# nrf51 register map
Vendor: Nordic Semiconductor; Series: nrf51; File version: 522
CPU: CM0 r3p1, little endian, no MPU, no FPU, 2 interrupt priority bits
Registers are 32-bit, read-write, reset 0x0 unless marked. A register's access mark holds for its fields unless they carry their own. Offsets are from the block's base; [hi:lo] are bit positions; 'fields as' and 'values as' point back to an identical list.

## SPI0 — SPI master 0.
Base 0x40003000
Same registers: SPI1 0x40004000
0x108 EVENTS_READY — TXD byte sent and RXD byte received.
0x304 INTENSET — Interrupt enable set register.
  [2] READY — Enable interrupt on READY event.
    on read: 0=Disabled (Interrupt disabled.); 1=Enabled (Interrupt enabled.) | on write: 1=Set (Enable interrupt on write.)
0x308 INTENCLR — Interrupt enable clear register.
  [2] READY — Disable interrupt on READY event.
    on read: 0=Disabled (Interrupt disabled.); 1=Enabled (Interrupt enabled.) | on write: 1=Clear (Disable interrupt on write.)
0x500 ENABLE — Enable SPI.
  [2:0] ENABLE — Enable or disable SPI.
    0=Disabled SPI; 1=Enabled (Enable SPI.)
0x508 PSELSCK reset 0xFFFFFFFF — Pin select for SCK.
0x50C PSELMOSI reset 0xFFFFFFFF — Pin select for MOSI.
0x510 PSELMISO reset 0xFFFFFFFF — Pin select for MISO.
0x518 RXD ro read-has-side-effects — RX data.
  [7:0] RXD — RX data from last transfer.
0x51C TXD — TX data.
  [7:0] TXD — TX data for next transfer.
0x524 FREQUENCY reset 0x4000000 — SPI frequency
  [31:0] FREQUENCY — SPI data rate.
    0x2000000=K125 (125kbps.); 0x4000000=K250 (250kbps.); 0x8000000=K500 (500kbps.); 0x10000000=M1 (1Mbps.); 0x20000000=M2 (2Mbps.); 0x40000000=M4 (4Mbps.); 0x80000000=M8 (8Mbps.)
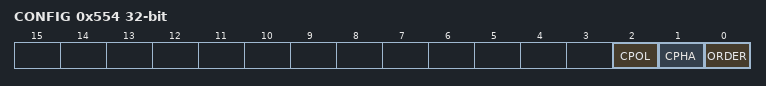
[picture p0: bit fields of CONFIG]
0x554 CONFIG — Configuration register.
  [2] CPOL — Serial clock (SCK) polarity.
    0=ActiveHigh; 1=ActiveLow
  [1] CPHA — Serial clock (SCK) phase.
    0=Leading (Sample on leading edge of the clock. Shift serial data on trailing edge.); 1=Trailing (Sample on trailing edge of the clock. Shift serial data on leading edge.)
  [0] ORDER — Bit order.
    0=MsbFirst (Most significant bit transmitted out first.); 1=LsbFirst (Least significant bit transmitted out first.)
0xFFC POWER — Peripheral power control.
  [0] POWER
    0=Disabled (Module power disabled.); 1=Enabled (Module power enabled.)

## TWI0 — Two-wire interface master 0.
Base 0x40003000; alternate view of SPI0
Same registers: TWI1 0x40004000 (alternate view of SPI1)
0x00 TASKS_STARTRX wo — Start 2-Wire master receive sequence.
0x08 TASKS_STARTTX wo — Start 2-Wire master transmit sequence.
0x14 TASKS_STOP wo — Stop 2-Wire transaction.
0x1C TASKS_SUSPEND wo — Suspend 2-Wire transaction.
0x20 TASKS_RESUME wo — Resume 2-Wire transaction.
0x104 EVENTS_STOPPED — Two-wire stopped.
0x108 EVENTS_RXDREADY — Two-wire ready to deliver new RXD byte received.
0x11C EVENTS_TXDSENT — Two-wire finished sending last TXD byte.
0x124 EVENTS_ERROR — Two-wire error detected.
0x138 EVENTS_BB — Two-wire byte boundary.
0x148 EVENTS_SUSPENDED — Two-wire suspended.
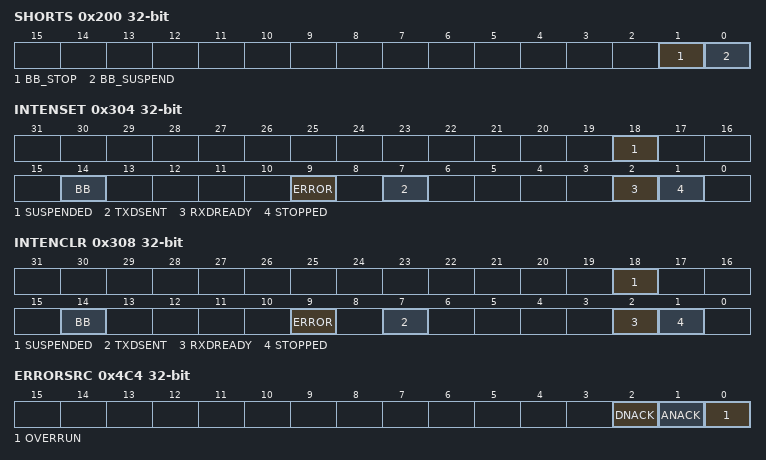
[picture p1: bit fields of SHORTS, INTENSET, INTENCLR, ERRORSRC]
0x200 SHORTS — Shortcuts for TWI.
  [1] BB_STOP — Shortcut between BB event and the STOP task.
    0=Disabled (Shortcut disabled.); 1=Enabled (Shortcut enabled.)
  [0] BB_SUSPEND — Shortcut between BB event and the SUSPEND task.
    values as BB_STOP
0x304 INTENSET — Interrupt enable set register.
  [all] fields
    on read: 0=Disabled (Interrupt disabled.); 1=Enabled (Interrupt enabled.) | on write: 1=Set (Enable interrupt on write.)
  [18] SUSPENDED — Enable interrupt on SUSPENDED event.
  [14] BB — Enable interrupt on BB event.
  [9] ERROR — Enable interrupt on ERROR event.
  [7] TXDSENT — Enable interrupt on TXDSENT event.
  [2] RXDREADY — Enable interrupt on READY event.
  [1] STOPPED — Enable interrupt on STOPPED event.
0x308 INTENCLR — Interrupt enable clear register.
  [all] fields
    on read: 0=Disabled (Interrupt disabled.); 1=Enabled (Interrupt enabled.) | on write: 1=Clear (Disable interrupt on write.)
  [18] SUSPENDED — Disable interrupt on SUSPENDED event.
  [14] BB — Disable interrupt on BB event.
  [9] ERROR — Disable interrupt on ERROR event.
  [7] TXDSENT — Disable interrupt on TXDSENT event.
  [2] RXDREADY — Disable interrupt on RXDREADY event.
  [1] STOPPED — Disable interrupt on STOPPED event.
0x4C4 ERRORSRC — Two-wire error source. Write error field to 1 to clear error.
  [all] fields
    on read: 0=NotPresent (Error not present.); 1=Present (Error present.) | on write: 1=Clear error on write
  [2] DNACK — NACK received after sending a data byte.
  [1] ANACK — NACK received after sending the address.
  [0] OVERRUN — Byte received in RXD register before read of the last received byte (data loss).
0x500 ENABLE — Enable two-wire master.
  [2:0] ENABLE — Enable or disable W2M
    0=Disabled; 5=Enabled
0x508 PSELSCL reset 0xFFFFFFFF — Pin select for SCL.
0x50C PSELSDA reset 0xFFFFFFFF — Pin select for SDA.
0x518 RXD ro read-has-side-effects — RX data register.
  [7:0] RXD — RX data from last transfer.
0x51C TXD — TX data register.
  [7:0] TXD — TX data for next transfer.
0x524 FREQUENCY reset 0x4000000 — Two-wire frequency.
  [31:0] FREQUENCY — Two-wire master clock frequency.
    0x1980000=K100 (100 kbps.); 0x4000000=K250 (250 kbps.); 0x6680000=K400 (400 kbps (actual rate 410.256 kbps).)
0x588 ADDRESS — Address used in the two-wire transfer.
  [6:0] ADDRESS — Two-wire address.
0xFFC POWER — Peripheral power control.
  [0] POWER
    0=Disabled (Module power disabled.); 1=Enabled (Module power enabled.)
